# CTRL_MODULE_CORE_PAD register map
Vendor: Texas Instruments
Registers are 32-bit, access per field, reset 0x10F010F unless marked. A register's access mark holds for its fields unless they carry their own. Offsets are as the file gives them; [hi:lo] are bit positions; {n}, {i} and the like mark numbered series; 'fields as' and 'values as' point back to an identical list.

## CTRL_MODULE_CORE_PAD (part 6 of 7)
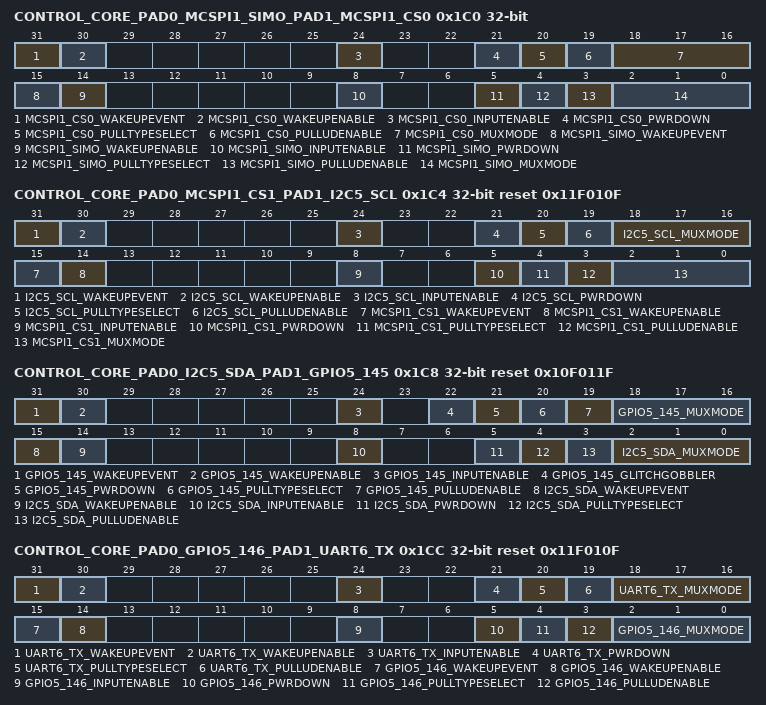
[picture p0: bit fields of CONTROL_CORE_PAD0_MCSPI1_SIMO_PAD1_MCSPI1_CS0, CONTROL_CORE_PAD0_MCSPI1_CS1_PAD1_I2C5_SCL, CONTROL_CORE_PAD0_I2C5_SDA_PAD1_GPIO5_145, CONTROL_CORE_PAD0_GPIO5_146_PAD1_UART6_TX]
0x1C0 CONTROL_CORE_PAD0_MCSPI1_SIMO_PAD1_MCSPI1_CS0 — Register control for Pads mcspi1_simo and mcspi1_cs0 Access conditions. Read: unrestricted, Write: unrestricted
  [31] MCSPI1_CS0_WAKEUPEVENT ro — Pad_x wake-up event status latched in the IO
    1=WakeUp (A wake-up event occurred); 0=No wake-up event occurred
  [30] MCSPI1_CS0_WAKEUPENABLE rw — Input pad wake-up enable
    0=DetectLow (wake-up detection is disabled); 1=DetectLowHigh (wake-up detection is enabled)
  [24] MCSPI1_CS0_INPUTENABLE rw — Input enable value for pad mcspi1_cs0
    0=InputBufferDisabled (Input buffer of IO cell is disabled); 1=InputBufferEnabled (Input buffer of IO cell is enabled)
  [21] MCSPI1_CS0_PWRDOWN rw — Power Down setting for pad mcspi1_cs0
    0=PwrDownDisabled (IO cell power is ON); 1=PwrDownEnabled (IO cell power is OFF)
  [20] MCSPI1_CS0_PULLTYPESELECT rw — Pull-Up/Down selection for pad mcspi1_cs0
    0=Pull-Down selected; 1=Pull-Up selected
  [19] MCSPI1_CS0_PULLUDENABLE rw — Pull-Up/Down enable for pad mcspi1_cs0
    0=PullDisabled (Pull-Up/Down disabled); 1=PullEnabled (Pull-Up/Down enabled)
  [18:16] MCSPI1_CS0_MUXMODE rw — Functional multiplexing selection for pad mcspi1_cs0
    0=SEL_MCSPI1_CS0 (Select mcspi1_cs0); 6=SEL_GPIO5_143 (Select gpio5_143); 7=SEL_SAFE_MODE_CORE173 (Select safe_mode_core173); 5=SEL_USBD0_ULPIPHY_DATA0 (Select usbd0_ulpiphy_data0)
  [15] MCSPI1_SIMO_WAKEUPEVENT ro — Pad_x wake-up event status latched in the IO
    values as MCSPI1_CS0_WAKEUPEVENT
  [14] MCSPI1_SIMO_WAKEUPENABLE rw — Input pad wake-up enable
    values as MCSPI1_CS0_WAKEUPENABLE
  [8] MCSPI1_SIMO_INPUTENABLE rw — Input enable value for pad mcspi1_simo
    values as MCSPI1_CS0_INPUTENABLE
  [5] MCSPI1_SIMO_PWRDOWN rw — Power Down setting for pad mcspi1_simo
    values as MCSPI1_CS0_PWRDOWN
  [4] MCSPI1_SIMO_PULLTYPESELECT rw — Pull-Up/Down selection for pad mcspi1_simo
    0=Pull-Down selected; 1=Pull-Up selected
  [3] MCSPI1_SIMO_PULLUDENABLE rw — Pull-Up/Down enable for pad mcspi1_simo
    values as MCSPI1_CS0_PULLUDENABLE
  [2:0] MCSPI1_SIMO_MUXMODE rw — Functional multiplexing selection for pad mcspi1_simo
    0=SEL_MCSPI1_SIMO (Select mcspi1_simo); 6=SEL_GPIO5_142 (Select gpio5_142); 7=SEL_SAFE_MODE_CORE172 (Select safe_mode_core172); 5=SEL_USBD0_ULPIPHY_DIR (Select usbd0_ulpiphy_dir)
0x1C4 CONTROL_CORE_PAD0_MCSPI1_CS1_PAD1_I2C5_SCL reset 0x11F010F — Register control for Pads mcspi1_cs1 and i2c5_scl Access conditions. Read: unrestricted, Write: unrestricted
  [31] I2C5_SCL_WAKEUPEVENT ro — Pad_x wake-up event status latched in the IO
    values as CONTROL_CORE_PAD0_MCSPI1_SIMO_PAD1_MCSPI1_CS0.MCSPI1_CS0_WAKEUPEVENT
  [30] I2C5_SCL_WAKEUPENABLE rw — Input pad wake-up enable
    values as CONTROL_CORE_PAD0_MCSPI1_SIMO_PAD1_MCSPI1_CS0.MCSPI1_CS0_WAKEUPENABLE
  [24] I2C5_SCL_INPUTENABLE rw — Input enable value for pad i2c5_scl
    values as CONTROL_CORE_PAD0_MCSPI1_SIMO_PAD1_MCSPI1_CS0.MCSPI1_CS0_INPUTENABLE
  [21] I2C5_SCL_PWRDOWN rw — Power Down setting for pad i2c5_scl
    values as CONTROL_CORE_PAD0_MCSPI1_SIMO_PAD1_MCSPI1_CS0.MCSPI1_CS0_PWRDOWN
  [20] I2C5_SCL_PULLTYPESELECT rw — Pull-Up/Down selection for pad i2c5_scl
    0=Pull-Down selected; 1=Pull-Up selected
  [19] I2C5_SCL_PULLUDENABLE rw — Pull-Up/Down enable for pad i2c5_scl
    values as CONTROL_CORE_PAD0_MCSPI1_SIMO_PAD1_MCSPI1_CS0.MCSPI1_CS0_PULLUDENABLE
  [18:16] I2C5_SCL_MUXMODE rw — Functional multiplexing selection for pad i2c5_scl
    0=SEL_I2C5_SCL (Select i2c5_scl); 6=SEL_GPIO5_147 (Select gpio5_147); 7=SEL_SAFE_MODE_CORE175 (Select safe_mode_core175); 2=SEL_UART4_RX (Select uart4_rx)
  [15] MCSPI1_CS1_WAKEUPEVENT ro — Pad_x wake-up event status latched in the IO
    values as CONTROL_CORE_PAD0_MCSPI1_SIMO_PAD1_MCSPI1_CS0.MCSPI1_CS0_WAKEUPEVENT
  [14] MCSPI1_CS1_WAKEUPENABLE rw — Input pad wake-up enable
    values as CONTROL_CORE_PAD0_MCSPI1_SIMO_PAD1_MCSPI1_CS0.MCSPI1_CS0_WAKEUPENABLE
  [8] MCSPI1_CS1_INPUTENABLE rw — Input enable value for pad mcspi1_cs1
    values as CONTROL_CORE_PAD0_MCSPI1_SIMO_PAD1_MCSPI1_CS0.MCSPI1_CS0_INPUTENABLE
  [5] MCSPI1_CS1_PWRDOWN rw — Power Down setting for pad mcspi1_cs1
    values as CONTROL_CORE_PAD0_MCSPI1_SIMO_PAD1_MCSPI1_CS0.MCSPI1_CS0_PWRDOWN
  [4] MCSPI1_CS1_PULLTYPESELECT rw — Pull-Up/Down selection for pad mcspi1_cs1
    0=Pull-Down selected; 1=Pull-Up selected
  [3] MCSPI1_CS1_PULLUDENABLE rw — Pull-Up/Down enable for pad mcspi1_cs1
    values as CONTROL_CORE_PAD0_MCSPI1_SIMO_PAD1_MCSPI1_CS0.MCSPI1_CS0_PULLUDENABLE
  [2:0] MCSPI1_CS1_MUXMODE rw — Functional multiplexing selection for pad mcspi1_cs1
    0=SEL_MCSPI1_CS1 (Select mcspi1_cs1); 6=SEL_GPIO5_144 (Select gpio5_144); 7=SEL_SAFE_MODE_CORE174 (Select safe_mode_core174); 5=SEL_USBD0_ULPIPHY_DATA1 (Select usbd0_ulpiphy_data1)
0x1C8 CONTROL_CORE_PAD0_I2C5_SDA_PAD1_GPIO5_145 reset 0x10F011F — Register control for Pads i2c5_sda and gpio5_145 Access conditions. Read: unrestricted, Write: unrestricted
  [31] GPIO5_145_WAKEUPEVENT ro — Pad_x wake-up event status latched in the IO
    values as CONTROL_CORE_PAD0_MCSPI1_SIMO_PAD1_MCSPI1_CS0.MCSPI1_CS0_WAKEUPEVENT
  [30] GPIO5_145_WAKEUPENABLE rw — Input pad wake-up enable
    values as CONTROL_CORE_PAD0_MCSPI1_SIMO_PAD1_MCSPI1_CS0.MCSPI1_CS0_WAKEUPENABLE
  [24] GPIO5_145_INPUTENABLE rw — Input enable value for pad gpio5_145
    values as CONTROL_CORE_PAD0_MCSPI1_SIMO_PAD1_MCSPI1_CS0.MCSPI1_CS0_INPUTENABLE
  [22] GPIO5_145_GLITCHGOBBLER rw — Glitch Gobbler setting for pad gpio5_145
    0=GlitchGobblerDisabled (IO do not Filter glitch from outside); 1=GlitchGobblerEnabled (IO Filter glitch from outside)
  [21] GPIO5_145_PWRDOWN rw — Power Down setting for pad gpio5_145
    values as CONTROL_CORE_PAD0_MCSPI1_SIMO_PAD1_MCSPI1_CS0.MCSPI1_CS0_PWRDOWN
  [20] GPIO5_145_PULLTYPESELECT rw — Pull-Up/Down selection for pad gpio5_145
    0=Pull-Down selected; 1=Pull-Up selected
  [19] GPIO5_145_PULLUDENABLE rw — Pull-Up/Down enable for pad gpio5_145
    values as CONTROL_CORE_PAD0_MCSPI1_SIMO_PAD1_MCSPI1_CS0.MCSPI1_CS0_PULLUDENABLE
  [18:16] GPIO5_145_MUXMODE rw — Functional multiplexing selection for pad gpio5_145
    6=SEL_GPIO5_145_1 (Select gpio5_145); 1=SEL_MCSPI1_CS2 (Select mcspi1_cs2); 7=SEL_SAFE_MODE_CORE177 (Select safe_mode_core177); 0=SEL_GPIO5_145 (Select gpio5_145); 2=SEL_UART4_CTS (Select uart4_cts); 5=SEL_USBD0_ULPIPHY_DATA2 (Select usbd0_ulpiphy_data2); 3=SEL_SDIO5_CLK (Select sdio5_clk)
  [15] I2C5_SDA_WAKEUPEVENT ro — Pad_x wake-up event status latched in the IO
    values as CONTROL_CORE_PAD0_MCSPI1_SIMO_PAD1_MCSPI1_CS0.MCSPI1_CS0_WAKEUPEVENT
  [14] I2C5_SDA_WAKEUPENABLE rw — Input pad wake-up enable
    values as CONTROL_CORE_PAD0_MCSPI1_SIMO_PAD1_MCSPI1_CS0.MCSPI1_CS0_WAKEUPENABLE
  [8] I2C5_SDA_INPUTENABLE rw — Input enable value for pad i2c5_sda
    values as CONTROL_CORE_PAD0_MCSPI1_SIMO_PAD1_MCSPI1_CS0.MCSPI1_CS0_INPUTENABLE
  [5] I2C5_SDA_PWRDOWN rw — Power Down setting for pad i2c5_sda
    values as CONTROL_CORE_PAD0_MCSPI1_SIMO_PAD1_MCSPI1_CS0.MCSPI1_CS0_PWRDOWN
  [4] I2C5_SDA_PULLTYPESELECT rw — Pull-Up/Down selection for pad i2c5_sda
    0=Pull-Down selected; 1=Pull-Up selected
  [3] I2C5_SDA_PULLUDENABLE rw — Pull-Up/Down enable for pad i2c5_sda
    values as CONTROL_CORE_PAD0_MCSPI1_SIMO_PAD1_MCSPI1_CS0.MCSPI1_CS0_PULLUDENABLE
  [2:0] I2C5_SDA_MUXMODE rw — Functional multiplexing selection for pad i2c5_sda
    0=SEL_I2C5_SDA (Select i2c5_sda); 6=SEL_GPIO5_148 (Select gpio5_148); 7=SEL_SAFE_MODE_CORE176 (Select safe_mode_core176); 2=SEL_UART4_TX (Select uart4_tx)
0x1CC CONTROL_CORE_PAD0_GPIO5_146_PAD1_UART6_TX reset 0x11F010F — Register control for Pads gpio5_146 and uart6_tx Access conditions. Read: unrestricted, Write: unrestricted
  [31] UART6_TX_WAKEUPEVENT ro — Pad_x wake-up event status latched in the IO
    values as CONTROL_CORE_PAD0_MCSPI1_SIMO_PAD1_MCSPI1_CS0.MCSPI1_CS0_WAKEUPEVENT
  [30] UART6_TX_WAKEUPENABLE rw — Input pad wake-up enable
    values as CONTROL_CORE_PAD0_MCSPI1_SIMO_PAD1_MCSPI1_CS0.MCSPI1_CS0_WAKEUPENABLE
  [24] UART6_TX_INPUTENABLE rw — Input enable value for pad uart6_tx
    values as CONTROL_CORE_PAD0_MCSPI1_SIMO_PAD1_MCSPI1_CS0.MCSPI1_CS0_INPUTENABLE
  [21] UART6_TX_PWRDOWN rw — Power Down setting for pad uart6_tx
    values as CONTROL_CORE_PAD0_MCSPI1_SIMO_PAD1_MCSPI1_CS0.MCSPI1_CS0_PWRDOWN
  [20] UART6_TX_PULLTYPESELECT rw — Pull-Up/Down selection for pad uart6_tx
    0=Pull-Down selected; 1=Pull-Up selected
  [19] UART6_TX_PULLUDENABLE rw — Pull-Up/Down enable for pad uart6_tx
    values as CONTROL_CORE_PAD0_MCSPI1_SIMO_PAD1_MCSPI1_CS0.MCSPI1_CS0_PULLUDENABLE
  [18:16] UART6_TX_MUXMODE rw — Functional multiplexing selection for pad uart6_tx
    0=SEL_UART6_TX (Select uart6_tx); 3=SEL_SDIO5_DATA3 (Select sdio5_data3); 7=SEL_SAFE_MODE_CORE179 (Select safe_mode_core179); 4=SEL_USBB2_MM_RXDP (Select usbb2_mm_rxdp); 6=SEL_GPIO5_149 (Select gpio5_149)
  [15] GPIO5_146_WAKEUPEVENT ro — Pad_x wake-up event status latched in the IO
    values as CONTROL_CORE_PAD0_MCSPI1_SIMO_PAD1_MCSPI1_CS0.MCSPI1_CS0_WAKEUPEVENT
  [14] GPIO5_146_WAKEUPENABLE rw — Input pad wake-up enable
    values as CONTROL_CORE_PAD0_MCSPI1_SIMO_PAD1_MCSPI1_CS0.MCSPI1_CS0_WAKEUPENABLE
  [8] GPIO5_146_INPUTENABLE rw — Input enable value for pad gpio5_146
    values as CONTROL_CORE_PAD0_MCSPI1_SIMO_PAD1_MCSPI1_CS0.MCSPI1_CS0_INPUTENABLE
  [5] GPIO5_146_PWRDOWN rw — Power Down setting for pad gpio5_146
    values as CONTROL_CORE_PAD0_MCSPI1_SIMO_PAD1_MCSPI1_CS0.MCSPI1_CS0_PWRDOWN
  [4] GPIO5_146_PULLTYPESELECT rw — Pull-Up/Down selection for pad gpio5_146
    0=Pull-Down selected; 1=Pull-Up selected
  [3] GPIO5_146_PULLUDENABLE rw — Pull-Up/Down enable for pad gpio5_146
    values as CONTROL_CORE_PAD0_MCSPI1_SIMO_PAD1_MCSPI1_CS0.MCSPI1_CS0_PULLUDENABLE
  [2:0] GPIO5_146_MUXMODE rw — Functional multiplexing selection for pad gpio5_146
    6=SEL_GPIO5_146_1 (Select gpio5_146); 1=SEL_MCSPI1_CS3 (Select mcspi1_cs3); 7=SEL_SAFE_MODE_CORE178 (Select safe_mode_core178); 0=SEL_GPIO5_146 (Select gpio5_146); 2=SEL_UART4_RTS (Select uart4_rts); 5=SEL_USBD0_ULPIPHY_DATA3 (Select usbd0_ulpiphy_data3); 3=SEL_SDIO5_CMD (Select sdio5_cmd)
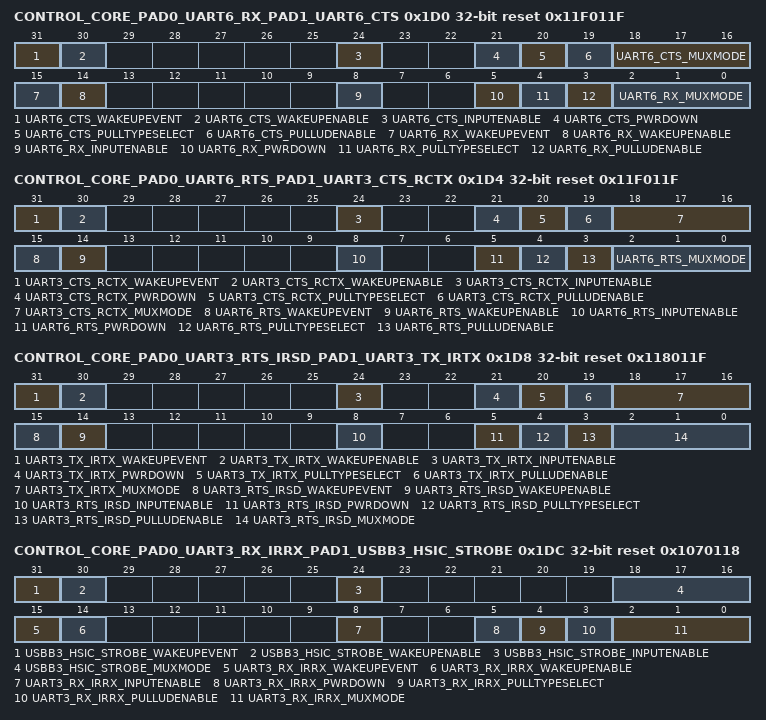
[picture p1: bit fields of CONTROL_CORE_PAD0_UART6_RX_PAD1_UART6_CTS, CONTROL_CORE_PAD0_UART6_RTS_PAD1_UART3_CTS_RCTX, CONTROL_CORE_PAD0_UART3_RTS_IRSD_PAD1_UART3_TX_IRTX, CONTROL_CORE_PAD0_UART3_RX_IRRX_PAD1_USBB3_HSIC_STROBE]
0x1D0 CONTROL_CORE_PAD0_UART6_RX_PAD1_UART6_CTS reset 0x11F011F — Register control for Pads uart6_rx and uart6_cts Access conditions. Read: unrestricted, Write: unrestricted
  [31] UART6_CTS_WAKEUPEVENT ro — Pad_x wake-up event status latched in the IO
    values as CONTROL_CORE_PAD0_MCSPI1_SIMO_PAD1_MCSPI1_CS0.MCSPI1_CS0_WAKEUPEVENT
  [30] UART6_CTS_WAKEUPENABLE rw — Input pad wake-up enable
    values as CONTROL_CORE_PAD0_MCSPI1_SIMO_PAD1_MCSPI1_CS0.MCSPI1_CS0_WAKEUPENABLE
  [24] UART6_CTS_INPUTENABLE rw — Input enable value for pad uart6_cts
    values as CONTROL_CORE_PAD0_MCSPI1_SIMO_PAD1_MCSPI1_CS0.MCSPI1_CS0_INPUTENABLE
  [21] UART6_CTS_PWRDOWN rw — Power Down setting for pad uart6_cts
    values as CONTROL_CORE_PAD0_MCSPI1_SIMO_PAD1_MCSPI1_CS0.MCSPI1_CS0_PWRDOWN
  [20] UART6_CTS_PULLTYPESELECT rw — Pull-Up/Down selection for pad uart6_cts
    0=Pull-Down selected; 1=Pull-Up selected
  [19] UART6_CTS_PULLUDENABLE rw — Pull-Up/Down enable for pad uart6_cts
    values as CONTROL_CORE_PAD0_MCSPI1_SIMO_PAD1_MCSPI1_CS0.MCSPI1_CS0_PULLUDENABLE
  [18:16] UART6_CTS_MUXMODE rw — Functional multiplexing selection for pad uart6_cts
    0=SEL_UART6_CTS (Select uart6_cts); 1=SEL_SYS_NDMAREQ1 (Select sys_ndmareq1); 3=SEL_SDIO5_DATA1 (Select sdio5_data1); 7=SEL_SAFE_MODE_CORE181 (Select safe_mode_core181); 4=SEL_USBB2_MM_RXRCV (Select usbb2_mm_rxrcv); 6=SEL_GPIO5_151 (Select gpio5_151)
  [15] UART6_RX_WAKEUPEVENT ro — Pad_x wake-up event status latched in the IO
    values as CONTROL_CORE_PAD0_MCSPI1_SIMO_PAD1_MCSPI1_CS0.MCSPI1_CS0_WAKEUPEVENT
  [14] UART6_RX_WAKEUPENABLE rw — Input pad wake-up enable
    values as CONTROL_CORE_PAD0_MCSPI1_SIMO_PAD1_MCSPI1_CS0.MCSPI1_CS0_WAKEUPENABLE
  [8] UART6_RX_INPUTENABLE rw — Input enable value for pad uart6_rx
    values as CONTROL_CORE_PAD0_MCSPI1_SIMO_PAD1_MCSPI1_CS0.MCSPI1_CS0_INPUTENABLE
  [5] UART6_RX_PWRDOWN rw — Power Down setting for pad uart6_rx
    values as CONTROL_CORE_PAD0_MCSPI1_SIMO_PAD1_MCSPI1_CS0.MCSPI1_CS0_PWRDOWN
  [4] UART6_RX_PULLTYPESELECT rw — Pull-Up/Down selection for pad uart6_rx
    0=Pull-Down selected; 1=Pull-Up selected
  [3] UART6_RX_PULLUDENABLE rw — Pull-Up/Down enable for pad uart6_rx
    values as CONTROL_CORE_PAD0_MCSPI1_SIMO_PAD1_MCSPI1_CS0.MCSPI1_CS0_PULLUDENABLE
  [2:0] UART6_RX_MUXMODE rw — Functional multiplexing selection for pad uart6_rx
    0=SEL_UART6_RX (Select uart6_rx); 3=SEL_SDIO5_DATA2 (Select sdio5_data2); 7=SEL_SAFE_MODE_CORE180 (Select safe_mode_core180); 4=SEL_USBB2_MM_RXDM (Select usbb2_mm_rxdm); 6=SEL_GPIO5_150 (Select gpio5_150)
0x1D4 CONTROL_CORE_PAD0_UART6_RTS_PAD1_UART3_CTS_RCTX reset 0x11F011F — Register control for Pads uart6_rts and uart3_cts_rctx Access conditions. Read: unrestricted, Write: unrestricted
  [31] UART3_CTS_RCTX_WAKEUPEVENT ro — Pad_x wake-up event status latched in the IO
    values as CONTROL_CORE_PAD0_MCSPI1_SIMO_PAD1_MCSPI1_CS0.MCSPI1_CS0_WAKEUPEVENT
  [30] UART3_CTS_RCTX_WAKEUPENABLE rw — Input pad wake-up enable
    values as CONTROL_CORE_PAD0_MCSPI1_SIMO_PAD1_MCSPI1_CS0.MCSPI1_CS0_WAKEUPENABLE
  [24] UART3_CTS_RCTX_INPUTENABLE rw — Input enable value for pad uart3_cts_rctx
    values as CONTROL_CORE_PAD0_MCSPI1_SIMO_PAD1_MCSPI1_CS0.MCSPI1_CS0_INPUTENABLE
  [21] UART3_CTS_RCTX_PWRDOWN rw — Power Down setting for pad uart3_cts_rctx
    values as CONTROL_CORE_PAD0_MCSPI1_SIMO_PAD1_MCSPI1_CS0.MCSPI1_CS0_PWRDOWN
  [20] UART3_CTS_RCTX_PULLTYPESELECT rw — Pull-Up/Down selection for pad uart3_cts_rctx
    0=Pull-Down selected; 1=Pull-Up selected
  [19] UART3_CTS_RCTX_PULLUDENABLE rw — Pull-Up/Down enable for pad uart3_cts_rctx
    values as CONTROL_CORE_PAD0_MCSPI1_SIMO_PAD1_MCSPI1_CS0.MCSPI1_CS0_PULLUDENABLE
  [18:16] UART3_CTS_RCTX_MUXMODE rw — Functional multiplexing selection for pad uart3_cts_rctx
    6=SEL_GPIO5_153 (Select gpio5_153); 1=SEL_SATA_ACTLED (Select sata_actled); 7=SEL_SAFE_MODE_CORE183 (Select safe_mode_core183); 0=SEL_UART3_CTS_RCTX (Select uart3_cts_rctx); 4=SEL_USBB2_MM_TXEN (Select usbb2_mm_txen); 5=SEL_USBD0_ULPIPHY_DATA4 (Select usbd0_ulpiphy_data4); 3=SEL_SDIO5_DATA7 (Select sdio5_data7)
  [15] UART6_RTS_WAKEUPEVENT ro — Pad_x wake-up event status latched in the IO
    values as CONTROL_CORE_PAD0_MCSPI1_SIMO_PAD1_MCSPI1_CS0.MCSPI1_CS0_WAKEUPEVENT
  [14] UART6_RTS_WAKEUPENABLE rw — Input pad wake-up enable
    values as CONTROL_CORE_PAD0_MCSPI1_SIMO_PAD1_MCSPI1_CS0.MCSPI1_CS0_WAKEUPENABLE
  [8] UART6_RTS_INPUTENABLE rw — Input enable value for pad uart6_rts
    values as CONTROL_CORE_PAD0_MCSPI1_SIMO_PAD1_MCSPI1_CS0.MCSPI1_CS0_INPUTENABLE
  [5] UART6_RTS_PWRDOWN rw — Power Down setting for pad uart6_rts
    values as CONTROL_CORE_PAD0_MCSPI1_SIMO_PAD1_MCSPI1_CS0.MCSPI1_CS0_PWRDOWN
  [4] UART6_RTS_PULLTYPESELECT rw — Pull-Up/Down selection for pad uart6_rts
    0=Pull-Down selected; 1=Pull-Up selected
  [3] UART6_RTS_PULLUDENABLE rw — Pull-Up/Down enable for pad uart6_rts
    values as CONTROL_CORE_PAD0_MCSPI1_SIMO_PAD1_MCSPI1_CS0.MCSPI1_CS0_PULLUDENABLE
  [2:0] UART6_RTS_MUXMODE rw — Functional multiplexing selection for pad uart6_rts
    6=SEL_GPIO5_152 (Select gpio5_152); 1=SEL_SYS_NDMAREQ0 (Select sys_ndmareq0); 7=SEL_SAFE_MODE_CORE182 (Select safe_mode_core182); 0=SEL_UART6_RTS (Select uart6_rts); 4=SEL_USBB2_MM_TXSE0 (Select usbb2_mm_txse0); 5=SEL_USBD0_ULPIPHY_STP (Select usbd0_ulpiphy_stp); 3=SEL_SDIO5_DATA0 (Select sdio5_data0)
0x1D8 CONTROL_CORE_PAD0_UART3_RTS_IRSD_PAD1_UART3_TX_IRTX reset 0x118011F — Register control for Pads uart3_rts_irsd and uart3_tx_irtx Access conditions. Read: unrestricted, Write: unrestricted
  [31] UART3_TX_IRTX_WAKEUPEVENT ro — Pad_x wake-up event status latched in the IO
    values as CONTROL_CORE_PAD0_MCSPI1_SIMO_PAD1_MCSPI1_CS0.MCSPI1_CS0_WAKEUPEVENT
  [30] UART3_TX_IRTX_WAKEUPENABLE rw — Input pad wake-up enable
    values as CONTROL_CORE_PAD0_MCSPI1_SIMO_PAD1_MCSPI1_CS0.MCSPI1_CS0_WAKEUPENABLE
  [24] UART3_TX_IRTX_INPUTENABLE rw — Input enable value for pad uart3_tx_irtx
    values as CONTROL_CORE_PAD0_MCSPI1_SIMO_PAD1_MCSPI1_CS0.MCSPI1_CS0_INPUTENABLE
  [21] UART3_TX_IRTX_PWRDOWN rw — Power Down setting for pad uart3_tx_irtx
    values as CONTROL_CORE_PAD0_MCSPI1_SIMO_PAD1_MCSPI1_CS0.MCSPI1_CS0_PWRDOWN
  [20] UART3_TX_IRTX_PULLTYPESELECT rw — Pull-Up/Down selection for pad uart3_tx_irtx
    0=Pull-Down selected; 1=Pull-Up selected
  [19] UART3_TX_IRTX_PULLUDENABLE rw — Pull-Up/Down enable for pad uart3_tx_irtx
    values as CONTROL_CORE_PAD0_MCSPI1_SIMO_PAD1_MCSPI1_CS0.MCSPI1_CS0_PULLUDENABLE
  [18:16] UART3_TX_IRTX_MUXMODE rw — Functional multiplexing selection for pad uart3_tx_irtx
    6=SEL_GPIO5_155 (Select gpio5_155); 7=SEL_SAFE_MODE_CORE185 (Select safe_mode_core185); 0=SEL_UART3_TX_IRTX (Select uart3_tx_irtx); 4=SEL_SDIO4_CLK (Select sdio4_clk); 5=SEL_USBD0_ULPIPHY_DATA6 (Select usbd0_ulpiphy_data6); 3=SEL_SDIO5_DATA5 (Select sdio5_data5)
  [15] UART3_RTS_IRSD_WAKEUPEVENT ro — Pad_x wake-up event status latched in the IO
    values as CONTROL_CORE_PAD0_MCSPI1_SIMO_PAD1_MCSPI1_CS0.MCSPI1_CS0_WAKEUPEVENT
  [14] UART3_RTS_IRSD_WAKEUPENABLE rw — Input pad wake-up enable
    values as CONTROL_CORE_PAD0_MCSPI1_SIMO_PAD1_MCSPI1_CS0.MCSPI1_CS0_WAKEUPENABLE
  [8] UART3_RTS_IRSD_INPUTENABLE rw — Input enable value for pad uart3_rts_irsd
    values as CONTROL_CORE_PAD0_MCSPI1_SIMO_PAD1_MCSPI1_CS0.MCSPI1_CS0_INPUTENABLE
  [5] UART3_RTS_IRSD_PWRDOWN rw — Power Down setting for pad uart3_rts_irsd
    values as CONTROL_CORE_PAD0_MCSPI1_SIMO_PAD1_MCSPI1_CS0.MCSPI1_CS0_PWRDOWN
  [4] UART3_RTS_IRSD_PULLTYPESELECT rw — Pull-Up/Down selection for pad uart3_rts_irsd
    0=Pull-Down selected; 1=Pull-Up selected
  [3] UART3_RTS_IRSD_PULLUDENABLE rw — Pull-Up/Down enable for pad uart3_rts_irsd
    values as CONTROL_CORE_PAD0_MCSPI1_SIMO_PAD1_MCSPI1_CS0.MCSPI1_CS0_PULLUDENABLE
  [2:0] UART3_RTS_IRSD_MUXMODE rw — Functional multiplexing selection for pad uart3_rts_irsd
    6=SEL_GPIO5_154 (Select gpio5_154); 1=SEL_HDQ_SIO (Select hdq_sio); 7=SEL_SAFE_MODE_CORE184 (Select safe_mode_core184); 0=SEL_UART3_RTS_IRSD (Select uart3_rts_irsd); 4=SEL_USBB2_MM_TXDAT (Select usbb2_mm_txdat); 5=SEL_USBD0_ULPIPHY_DATA5 (Select usbd0_ulpiphy_data5); 3=SEL_SDIO5_DATA6 (Select sdio5_data6)
0x1DC CONTROL_CORE_PAD0_UART3_RX_IRRX_PAD1_USBB3_HSIC_STROBE reset 0x1070118 — Register control for Pads uart3_rx_irrx and usbb3_hsic_strobe Access conditions. Read: unrestricted, Write: unrestricted
  [31] USBB3_HSIC_STROBE_WAKEUPEVENT ro — Pad_x wake-up event status latched in the IO
    values as CONTROL_CORE_PAD0_MCSPI1_SIMO_PAD1_MCSPI1_CS0.MCSPI1_CS0_WAKEUPEVENT
  [30] USBB3_HSIC_STROBE_WAKEUPENABLE rw — Input pad wake-up enable
    values as CONTROL_CORE_PAD0_MCSPI1_SIMO_PAD1_MCSPI1_CS0.MCSPI1_CS0_WAKEUPENABLE
  [24] USBB3_HSIC_STROBE_INPUTENABLE rw — Input enable value for pad usbb3_hsic_strobe
    values as CONTROL_CORE_PAD0_MCSPI1_SIMO_PAD1_MCSPI1_CS0.MCSPI1_CS0_INPUTENABLE
  [18:16] USBB3_HSIC_STROBE_MUXMODE rw — Functional multiplexing selection for pad usbb3_hsic_strobe
    0=SEL_USBB3_HSIC_STROBE (Select usbb3_hsic_strobe); 7=SEL_SAFE_MODE_CORE187 (Select safe_mode_core187); 6=SEL_GPIO5_158 (Select gpio5_158)
  [15] UART3_RX_IRRX_WAKEUPEVENT ro — Pad_x wake-up event status latched in the IO
    values as CONTROL_CORE_PAD0_MCSPI1_SIMO_PAD1_MCSPI1_CS0.MCSPI1_CS0_WAKEUPEVENT
  [14] UART3_RX_IRRX_WAKEUPENABLE rw — Input pad wake-up enable
    values as CONTROL_CORE_PAD0_MCSPI1_SIMO_PAD1_MCSPI1_CS0.MCSPI1_CS0_WAKEUPENABLE
  [8] UART3_RX_IRRX_INPUTENABLE rw — Input enable value for pad uart3_rx_irrx
    values as CONTROL_CORE_PAD0_MCSPI1_SIMO_PAD1_MCSPI1_CS0.MCSPI1_CS0_INPUTENABLE
  [5] UART3_RX_IRRX_PWRDOWN rw — Power Down setting for pad uart3_rx_irrx
    values as CONTROL_CORE_PAD0_MCSPI1_SIMO_PAD1_MCSPI1_CS0.MCSPI1_CS0_PWRDOWN
  [4] UART3_RX_IRRX_PULLTYPESELECT rw — Pull-Up/Down selection for pad uart3_rx_irrx
    0=Pull-Down selected; 1=Pull-Up selected
  [3] UART3_RX_IRRX_PULLUDENABLE rw — Pull-Up/Down enable for pad uart3_rx_irrx
    values as CONTROL_CORE_PAD0_MCSPI1_SIMO_PAD1_MCSPI1_CS0.MCSPI1_CS0_PULLUDENABLE
  [2:0] UART3_RX_IRRX_MUXMODE rw — Functional multiplexing selection for pad uart3_rx_irrx
    6=SEL_GPIO5_156 (Select gpio5_156); 7=SEL_SAFE_MODE_CORE186 (Select safe_mode_core186); 0=SEL_UART3_RX_IRRX (Select uart3_rx_irrx); 4=SEL_SDIO4_CMD (Select sdio4_cmd); 5=SEL_USBD0_ULPIPHY_DATA7 (Select usbd0_ulpiphy_data7); 3=SEL_SDIO5_DATA4 (Select sdio5_data4)
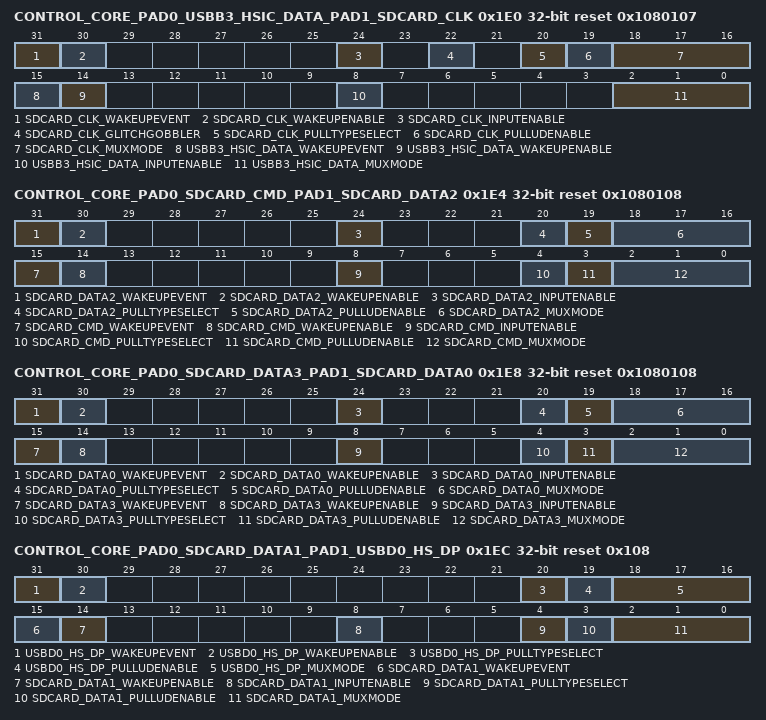
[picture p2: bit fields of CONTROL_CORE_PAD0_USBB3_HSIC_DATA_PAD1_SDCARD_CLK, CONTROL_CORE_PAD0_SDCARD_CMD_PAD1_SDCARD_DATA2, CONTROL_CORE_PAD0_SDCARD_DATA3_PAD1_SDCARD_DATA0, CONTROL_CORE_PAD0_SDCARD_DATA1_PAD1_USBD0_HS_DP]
0x1E0 CONTROL_CORE_PAD0_USBB3_HSIC_DATA_PAD1_SDCARD_CLK reset 0x1080107 — Register control for Pads usbb3_hsic_data and sdcard_clk Access conditions. Read: unrestricted, Write: unrestricted
  [31] SDCARD_CLK_WAKEUPEVENT ro — Pad_x wake-up event status latched in the IO
    values as CONTROL_CORE_PAD0_MCSPI1_SIMO_PAD1_MCSPI1_CS0.MCSPI1_CS0_WAKEUPEVENT
  [30] SDCARD_CLK_WAKEUPENABLE rw — Input pad wake-up enable
    values as CONTROL_CORE_PAD0_MCSPI1_SIMO_PAD1_MCSPI1_CS0.MCSPI1_CS0_WAKEUPENABLE
  [24] SDCARD_CLK_INPUTENABLE rw — Input enable value for pad sdcard_clk
    values as CONTROL_CORE_PAD0_MCSPI1_SIMO_PAD1_MCSPI1_CS0.MCSPI1_CS0_INPUTENABLE
  [22] SDCARD_CLK_GLITCHGOBBLER rw — Glitch Gobbler setting for pad sdcard_clk
    values as CONTROL_CORE_PAD0_I2C5_SDA_PAD1_GPIO5_145.GPIO5_145_GLITCHGOBBLER
  [20] SDCARD_CLK_PULLTYPESELECT rw — Pull-Up/Down selection for pad sdcard_clk
    0=Pull-Down selected; 1=Pull-Up selected
  [19] SDCARD_CLK_PULLUDENABLE rw — Pull-Up/Down enable for pad sdcard_clk
    values as CONTROL_CORE_PAD0_MCSPI1_SIMO_PAD1_MCSPI1_CS0.MCSPI1_CS0_PULLUDENABLE
  [18:16] SDCARD_CLK_MUXMODE rw — Functional multiplexing selection for pad sdcard_clk
    0=SEL_SDCARD_CLK (Select sdcard_clk); 3=SEL_JTAG_RTCK (Select jtag_rtck); 7=SEL_SAFE_MODE_CORE189 (Select safe_mode_core189); 5=SEL_N_CLK (Select n_clk)
  [15] USBB3_HSIC_DATA_WAKEUPEVENT ro — Pad_x wake-up event status latched in the IO
    values as CONTROL_CORE_PAD0_MCSPI1_SIMO_PAD1_MCSPI1_CS0.MCSPI1_CS0_WAKEUPEVENT
  [14] USBB3_HSIC_DATA_WAKEUPENABLE rw — Input pad wake-up enable
    values as CONTROL_CORE_PAD0_MCSPI1_SIMO_PAD1_MCSPI1_CS0.MCSPI1_CS0_WAKEUPENABLE
  [8] USBB3_HSIC_DATA_INPUTENABLE rw — Input enable value for pad usbb3_hsic_data
    values as CONTROL_CORE_PAD0_MCSPI1_SIMO_PAD1_MCSPI1_CS0.MCSPI1_CS0_INPUTENABLE
  [2:0] USBB3_HSIC_DATA_MUXMODE rw — Functional multiplexing selection for pad usbb3_hsic_data
    0=SEL_USBB3_HSIC_DATA (Select usbb3_hsic_data); 7=SEL_SAFE_MODE_CORE188 (Select safe_mode_core188); 6=SEL_GPIO5_159 (Select gpio5_159)
0x1E4 CONTROL_CORE_PAD0_SDCARD_CMD_PAD1_SDCARD_DATA2 reset 0x1080108 — Register control for Pads sdcard_cmd and sdcard_data2 Access conditions. Read: unrestricted, Write: unrestricted
  [31] SDCARD_DATA2_WAKEUPEVENT ro — Pad_x wake-up event status latched in the IO
    values as CONTROL_CORE_PAD0_MCSPI1_SIMO_PAD1_MCSPI1_CS0.MCSPI1_CS0_WAKEUPEVENT
  [30] SDCARD_DATA2_WAKEUPENABLE rw — Input pad wake-up enable
    values as CONTROL_CORE_PAD0_MCSPI1_SIMO_PAD1_MCSPI1_CS0.MCSPI1_CS0_WAKEUPENABLE
  [24] SDCARD_DATA2_INPUTENABLE rw — Input enable value for pad sdcard_data2
    values as CONTROL_CORE_PAD0_MCSPI1_SIMO_PAD1_MCSPI1_CS0.MCSPI1_CS0_INPUTENABLE
  [20] SDCARD_DATA2_PULLTYPESELECT rw — Pull-Up/Down selection for pad sdcard_data2
    0=Pull-Down selected; 1=Pull-Up selected
  [19] SDCARD_DATA2_PULLUDENABLE rw — Pull-Up/Down enable for pad sdcard_data2
    values as CONTROL_CORE_PAD0_MCSPI1_SIMO_PAD1_MCSPI1_CS0.MCSPI1_CS0_PULLUDENABLE
  [18:16] SDCARD_DATA2_MUXMODE rw — Functional multiplexing selection for pad sdcard_data2
    0=SEL_SDCARD_DATA2 (Select sdcard_data2); 3=SEL_JTAG_TMSC (Select jtag_tmsc); 7=SEL_SAFE_MODE_CORE193 (Select safe_mode_core193); 5=SEL_N_D2 (Select n_d2)
  [15] SDCARD_CMD_WAKEUPEVENT ro — Pad_x wake-up event status latched in the IO
    values as CONTROL_CORE_PAD0_MCSPI1_SIMO_PAD1_MCSPI1_CS0.MCSPI1_CS0_WAKEUPEVENT
  [14] SDCARD_CMD_WAKEUPENABLE rw — Input pad wake-up enable
    values as CONTROL_CORE_PAD0_MCSPI1_SIMO_PAD1_MCSPI1_CS0.MCSPI1_CS0_WAKEUPENABLE
  [8] SDCARD_CMD_INPUTENABLE rw — Input enable value for pad sdcard_cmd
    values as CONTROL_CORE_PAD0_MCSPI1_SIMO_PAD1_MCSPI1_CS0.MCSPI1_CS0_INPUTENABLE
  [4] SDCARD_CMD_PULLTYPESELECT rw — Pull-Up/Down selection for pad sdcard_cmd
    0=Pull-Down selected; 1=Pull-Up selected
  [3] SDCARD_CMD_PULLUDENABLE rw — Pull-Up/Down enable for pad sdcard_cmd
    values as CONTROL_CORE_PAD0_MCSPI1_SIMO_PAD1_MCSPI1_CS0.MCSPI1_CS0_PULLUDENABLE
  [2:0] SDCARD_CMD_MUXMODE rw — Functional multiplexing selection for pad sdcard_cmd
    0=SEL_SDCARD_CMD (Select sdcard_cmd); 3=SEL_JTAG_TDO (Select jtag_tdo); 7=SEL_SAFE_MODE_CORE190 (Select safe_mode_core190); 4=SEL_UART6_RX (Select uart6_rx); 6=SEL_N_D2 (Select n_d2)
0x1E8 CONTROL_CORE_PAD0_SDCARD_DATA3_PAD1_SDCARD_DATA0 reset 0x1080108 — Register control for Pads sdcard_data3 and sdcard_data0 Access conditions. Read: unrestricted, Write: unrestricted
  [31] SDCARD_DATA0_WAKEUPEVENT ro — Pad_x wake-up event status latched in the IO
    values as CONTROL_CORE_PAD0_MCSPI1_SIMO_PAD1_MCSPI1_CS0.MCSPI1_CS0_WAKEUPEVENT
  [30] SDCARD_DATA0_WAKEUPENABLE rw — Input pad wake-up enable
    values as CONTROL_CORE_PAD0_MCSPI1_SIMO_PAD1_MCSPI1_CS0.MCSPI1_CS0_WAKEUPENABLE
  [24] SDCARD_DATA0_INPUTENABLE rw — Input enable value for pad sdcard_data0
    values as CONTROL_CORE_PAD0_MCSPI1_SIMO_PAD1_MCSPI1_CS0.MCSPI1_CS0_INPUTENABLE
  [20] SDCARD_DATA0_PULLTYPESELECT rw — Pull-Up/Down selection for pad sdcard_data0
    0=Pull-Down selected; 1=Pull-Up selected
  [19] SDCARD_DATA0_PULLUDENABLE rw — Pull-Up/Down enable for pad sdcard_data0
    values as CONTROL_CORE_PAD0_MCSPI1_SIMO_PAD1_MCSPI1_CS0.MCSPI1_CS0_PULLUDENABLE
  [18:16] SDCARD_DATA0_MUXMODE rw — Functional multiplexing selection for pad sdcard_data0
    0=SEL_SDCARD_DATA0 (Select sdcard_data0); 3=SEL_JTAG_TDI (Select jtag_tdi); 7=SEL_SAFE_MODE_CORE191 (Select safe_mode_core191); 5=SEL_N_D0 (Select n_d0)
  [15] SDCARD_DATA3_WAKEUPEVENT ro — Pad_x wake-up event status latched in the IO
    values as CONTROL_CORE_PAD0_MCSPI1_SIMO_PAD1_MCSPI1_CS0.MCSPI1_CS0_WAKEUPEVENT
  [14] SDCARD_DATA3_WAKEUPENABLE rw — Input pad wake-up enable
    values as CONTROL_CORE_PAD0_MCSPI1_SIMO_PAD1_MCSPI1_CS0.MCSPI1_CS0_WAKEUPENABLE
  [8] SDCARD_DATA3_INPUTENABLE rw — Input enable value for pad sdcard_data3
    values as CONTROL_CORE_PAD0_MCSPI1_SIMO_PAD1_MCSPI1_CS0.MCSPI1_CS0_INPUTENABLE
  [4] SDCARD_DATA3_PULLTYPESELECT rw — Pull-Up/Down selection for pad sdcard_data3
    0=Pull-Down selected; 1=Pull-Up selected
  [3] SDCARD_DATA3_PULLUDENABLE rw — Pull-Up/Down enable for pad sdcard_data3
    values as CONTROL_CORE_PAD0_MCSPI1_SIMO_PAD1_MCSPI1_CS0.MCSPI1_CS0_PULLUDENABLE
  [2:0] SDCARD_DATA3_MUXMODE rw — Functional multiplexing selection for pad sdcard_data3
    0=SEL_SDCARD_DATA3 (Select sdcard_data3); 3=SEL_JTAG_TCK (Select jtag_tck); 7=SEL_SAFE_MODE_CORE194 (Select safe_mode_core194); 5=SEL_N_D3 (Select n_d3)
0x1EC CONTROL_CORE_PAD0_SDCARD_DATA1_PAD1_USBD0_HS_DP reset 0x108 — Register control for Pads sdcard_data1 and usbd0_hs_dp Access conditions. Read: unrestricted, Write: unrestricted
  [31] USBD0_HS_DP_WAKEUPEVENT ro — Pad_x wake-up event status latched in the IO
    values as CONTROL_CORE_PAD0_MCSPI1_SIMO_PAD1_MCSPI1_CS0.MCSPI1_CS0_WAKEUPEVENT
  [30] USBD0_HS_DP_WAKEUPENABLE rw — Input pad wake-up enable
    values as CONTROL_CORE_PAD0_MCSPI1_SIMO_PAD1_MCSPI1_CS0.MCSPI1_CS0_WAKEUPENABLE
  [20] USBD0_HS_DP_PULLTYPESELECT rw — Pull-Up/Down selection for pad usbd0_hs_dp
    0=Pull-Down selected; 1=Pull-Up selected
  [19] USBD0_HS_DP_PULLUDENABLE rw — Pull-Up/Down enable for pad usbd0_hs_dp
    values as CONTROL_CORE_PAD0_MCSPI1_SIMO_PAD1_MCSPI1_CS0.MCSPI1_CS0_PULLUDENABLE
  [18:16] USBD0_HS_DP_MUXMODE rw — Functional multiplexing selection for pad usbd0_hs_dp
    0=SEL_USBD0_HS_DP (Select usbd0_hs_dp); 4=SEL_UART3_RX_IRRX (Select uart3_rx_irrx); 7=SEL_SAFE_MODE_CORE195 (Select safe_mode_core195)
  [15] SDCARD_DATA1_WAKEUPEVENT ro — Pad_x wake-up event status latched in the IO
    values as CONTROL_CORE_PAD0_MCSPI1_SIMO_PAD1_MCSPI1_CS0.MCSPI1_CS0_WAKEUPEVENT
  [14] SDCARD_DATA1_WAKEUPENABLE rw — Input pad wake-up enable
    values as CONTROL_CORE_PAD0_MCSPI1_SIMO_PAD1_MCSPI1_CS0.MCSPI1_CS0_WAKEUPENABLE
  [8] SDCARD_DATA1_INPUTENABLE rw — Input enable value for pad sdcard_data1
    values as CONTROL_CORE_PAD0_MCSPI1_SIMO_PAD1_MCSPI1_CS0.MCSPI1_CS0_INPUTENABLE
  [4] SDCARD_DATA1_PULLTYPESELECT rw — Pull-Up/Down selection for pad sdcard_data1
    0=Pull-Down selected; 1=Pull-Up selected
  [3] SDCARD_DATA1_PULLUDENABLE rw — Pull-Up/Down enable for pad sdcard_data1
    values as CONTROL_CORE_PAD0_MCSPI1_SIMO_PAD1_MCSPI1_CS0.MCSPI1_CS0_PULLUDENABLE
  [2:0] SDCARD_DATA1_MUXMODE rw — Functional multiplexing selection for pad sdcard_data1
    0=SEL_SDCARD_DATA1 (Select sdcard_data1); 3=SEL_JTAG_NTRST (Select jtag_ntrst); 7=SEL_SAFE_MODE_CORE192 (Select safe_mode_core192); 5=SEL_N_D1 (Select n_d1)
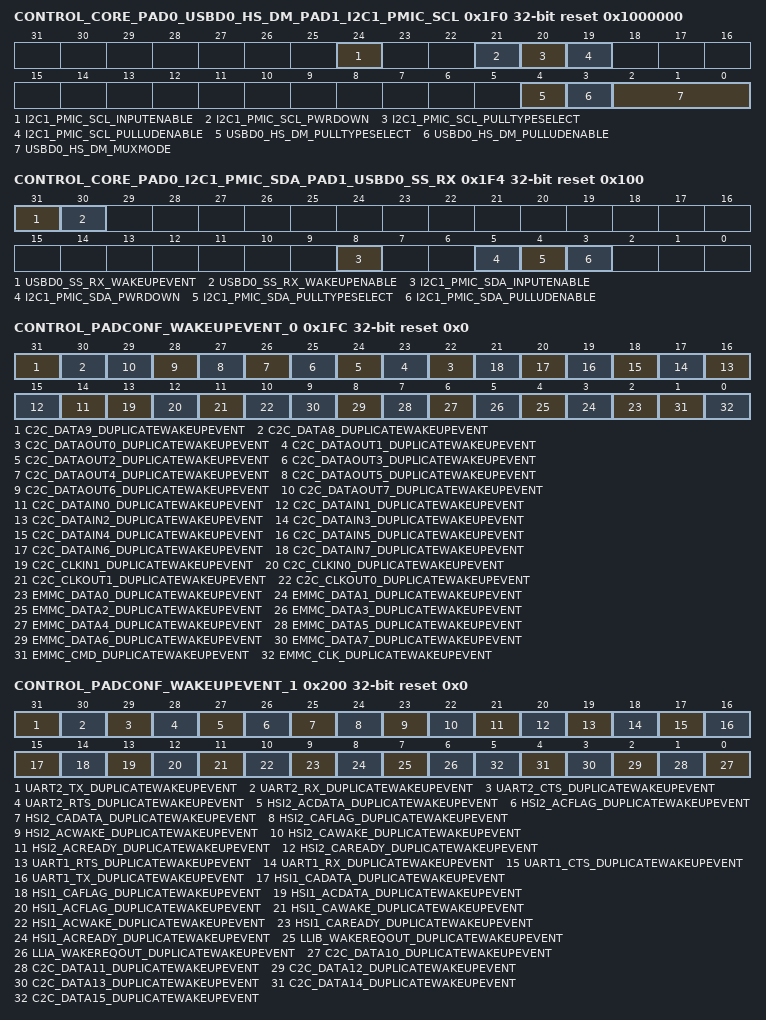
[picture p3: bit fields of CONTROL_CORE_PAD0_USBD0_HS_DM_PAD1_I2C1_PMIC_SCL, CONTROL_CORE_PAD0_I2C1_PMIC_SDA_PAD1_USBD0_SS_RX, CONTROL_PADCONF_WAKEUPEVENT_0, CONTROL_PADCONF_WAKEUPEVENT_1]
0x1F0 CONTROL_CORE_PAD0_USBD0_HS_DM_PAD1_I2C1_PMIC_SCL reset 0x1000000 — Register control for Pads usbd0_hs_dm and i2c1_pmic_scl Access conditions. Read: unrestricted, Write: unrestricted
  [24] I2C1_PMIC_SCL_INPUTENABLE rw — Input enable value for pad i2c1_pmic_scl
    values as CONTROL_CORE_PAD0_MCSPI1_SIMO_PAD1_MCSPI1_CS0.MCSPI1_CS0_INPUTENABLE
  [21] I2C1_PMIC_SCL_PWRDOWN rw — Power Down setting for pad i2c1_pmic_scl
    values as CONTROL_CORE_PAD0_MCSPI1_SIMO_PAD1_MCSPI1_CS0.MCSPI1_CS0_PWRDOWN
  [20] I2C1_PMIC_SCL_PULLTYPESELECT rw — Pull-Up/Down selection for pad i2c1_pmic_scl
    0=Pull-Down selected; 1=Pull-Up selected
  [19] I2C1_PMIC_SCL_PULLUDENABLE rw — Pull-Up/Down enable for pad i2c1_pmic_scl
    values as CONTROL_CORE_PAD0_MCSPI1_SIMO_PAD1_MCSPI1_CS0.MCSPI1_CS0_PULLUDENABLE
  [4] USBD0_HS_DM_PULLTYPESELECT rw — Pull-Up/Down selection for pad usbd0_hs_dm
    0=Pull-Down selected; 1=Pull-Up selected
  [3] USBD0_HS_DM_PULLUDENABLE rw — Pull-Up/Down enable for pad usbd0_hs_dm
    values as CONTROL_CORE_PAD0_MCSPI1_SIMO_PAD1_MCSPI1_CS0.MCSPI1_CS0_PULLUDENABLE
  [2:0] USBD0_HS_DM_MUXMODE rw — Functional multiplexing selection for pad usbd0_hs_dm
    0=SEL_USBD0_HS_DM (Select usbd0_hs_dm); 4=SEL_UART3_TX_IRTX (Select uart3_tx_irtx); 7=SEL_SAFE_MODE_CORE196 (Select safe_mode_core196)
0x1F4 CONTROL_CORE_PAD0_I2C1_PMIC_SDA_PAD1_USBD0_SS_RX reset 0x100 — Register control for Pads i2c1_pmic_sda and usbd0_ss_rx Access conditions. Read: unrestricted, Write: unrestricted
  [31] USBD0_SS_RX_WAKEUPEVENT ro — Pad_x wake-up event status latched in the IO
    values as CONTROL_CORE_PAD0_MCSPI1_SIMO_PAD1_MCSPI1_CS0.MCSPI1_CS0_WAKEUPEVENT
  [30] USBD0_SS_RX_WAKEUPENABLE rw — Input pad wake-up enable
    values as CONTROL_CORE_PAD0_MCSPI1_SIMO_PAD1_MCSPI1_CS0.MCSPI1_CS0_WAKEUPENABLE
  [8] I2C1_PMIC_SDA_INPUTENABLE rw — Input enable value for pad i2c1_pmic_sda
    values as CONTROL_CORE_PAD0_MCSPI1_SIMO_PAD1_MCSPI1_CS0.MCSPI1_CS0_INPUTENABLE
  [5] I2C1_PMIC_SDA_PWRDOWN rw — Power Down setting for pad i2c1_pmic_sda
    values as CONTROL_CORE_PAD0_MCSPI1_SIMO_PAD1_MCSPI1_CS0.MCSPI1_CS0_PWRDOWN
  [4] I2C1_PMIC_SDA_PULLTYPESELECT rw — Pull-Up/Down selection for pad i2c1_pmic_sda
    0=Pull-Down selected; 1=Pull-Up selected
  [3] I2C1_PMIC_SDA_PULLUDENABLE rw — Pull-Up/Down enable for pad i2c1_pmic_sda
    values as CONTROL_CORE_PAD0_MCSPI1_SIMO_PAD1_MCSPI1_CS0.MCSPI1_CS0_PULLUDENABLE
0x1FC CONTROL_PADCONF_WAKEUPEVENT_0 ro reset 0x0 — Access conditions. Read: unrestricted, Write: unrestricted
  [all] fields
    1=WakeUp (A wakeup event occurred); 0=No wakeup event occurred
  [31] C2C_DATA9_DUPLICATEWAKEUPEVENT — Wake-up event status latched in the IO for pad c2c_data9
  [30] C2C_DATA8_DUPLICATEWAKEUPEVENT — Wake-up event status latched in the IO for pad c2c_data8
  [n+22] C2C_DATAOUT{n}_DUPLICATEWAKEUPEVENT (n=0..7) — Wake-up event status latched in the IO for pad c2c_dataout{n}
  [n+14] C2C_DATAIN{n}_DUPLICATEWAKEUPEVENT (n=0..7) — Wake-up event status latched in the IO for pad c2c_datain{n}
  [13] C2C_CLKIN1_DUPLICATEWAKEUPEVENT — Wake-up event status latched in the IO for pad c2c_clkin1
  [12] C2C_CLKIN0_DUPLICATEWAKEUPEVENT — Wake-up event status latched in the IO for pad c2c_clkin0
  [11] C2C_CLKOUT1_DUPLICATEWAKEUPEVENT — Wake-up event status latched in the IO for pad c2c_clkout1
  [10] C2C_CLKOUT0_DUPLICATEWAKEUPEVENT — Wake-up event status latched in the IO for pad c2c_clkout0
  [n+2] EMMC_DATA{n}_DUPLICATEWAKEUPEVENT (n=0..7) — Wake-up event status latched in the IO for pad emmc_data{n}
  [1] EMMC_CMD_DUPLICATEWAKEUPEVENT — Wake-up event status latched in the IO for pad emmc_cmd
  [0] EMMC_CLK_DUPLICATEWAKEUPEVENT — Wake-up event status latched in the IO for pad emmc_clk
0x200 CONTROL_PADCONF_WAKEUPEVENT_1 ro reset 0x0 — Access conditions. Read: unrestricted, Write: unrestricted
  [all] fields
    values as the fields of CONTROL_PADCONF_WAKEUPEVENT_0
  [31] UART2_TX_DUPLICATEWAKEUPEVENT — Wake-up event status latched in the IO for pad uart2_tx
  [30] UART2_RX_DUPLICATEWAKEUPEVENT — Wake-up event status latched in the IO for pad uart2_rx
  [29] UART2_CTS_DUPLICATEWAKEUPEVENT — Wake-up event status latched in the IO for pad uart2_cts
  [28] UART2_RTS_DUPLICATEWAKEUPEVENT — Wake-up event status latched in the IO for pad uart2_rts
  [27] HSI2_ACDATA_DUPLICATEWAKEUPEVENT — Wake-up event status latched in the IO for pad hsi2_acdata
  [26] HSI2_ACFLAG_DUPLICATEWAKEUPEVENT — Wake-up event status latched in the IO for pad hsi2_acflag
  [25] HSI2_CADATA_DUPLICATEWAKEUPEVENT — Wake-up event status latched in the IO for pad hsi2_cadata
  [24] HSI2_CAFLAG_DUPLICATEWAKEUPEVENT — Wake-up event status latched in the IO for pad hsi2_caflag
  [23] HSI2_ACWAKE_DUPLICATEWAKEUPEVENT — Wake-up event status latched in the IO for pad hsi2_acwake
  [22] HSI2_CAWAKE_DUPLICATEWAKEUPEVENT — Wake-up event status latched in the IO for pad hsi2_cawake
  [21] HSI2_ACREADY_DUPLICATEWAKEUPEVENT — Wake-up event status latched in the IO for pad hsi2_acready
  [20] HSI2_CAREADY_DUPLICATEWAKEUPEVENT — Wake-up event status latched in the IO for pad hsi2_caready
  [19] UART1_RTS_DUPLICATEWAKEUPEVENT — Wake-up event status latched in the IO for pad uart1_rts
  [18] UART1_RX_DUPLICATEWAKEUPEVENT — Wake-up event status latched in the IO for pad uart1_rx
  [17] UART1_CTS_DUPLICATEWAKEUPEVENT — Wake-up event status latched in the IO for pad uart1_cts
  [16] UART1_TX_DUPLICATEWAKEUPEVENT — Wake-up event status latched in the IO for pad uart1_tx
  [15] HSI1_CADATA_DUPLICATEWAKEUPEVENT — Wake-up event status latched in the IO for pad hsi1_cadata
  [14] HSI1_CAFLAG_DUPLICATEWAKEUPEVENT — Wake-up event status latched in the IO for pad hsi1_caflag
  [13] HSI1_ACDATA_DUPLICATEWAKEUPEVENT — Wake-up event status latched in the IO for pad hsi1_acdata
  [12] HSI1_ACFLAG_DUPLICATEWAKEUPEVENT — Wake-up event status latched in the IO for pad hsi1_acflag
  [11] HSI1_CAWAKE_DUPLICATEWAKEUPEVENT — Wake-up event status latched in the IO for pad hsi1_cawake
  [10] HSI1_ACWAKE_DUPLICATEWAKEUPEVENT — Wake-up event status latched in the IO for pad hsi1_acwake
  [9] HSI1_CAREADY_DUPLICATEWAKEUPEVENT — Wake-up event status latched in the IO for pad hsi1_caready
  [8] HSI1_ACREADY_DUPLICATEWAKEUPEVENT — Wake-up event status latched in the IO for pad hsi1_acready
  [7] LLIB_WAKEREQOUT_DUPLICATEWAKEUPEVENT — Wake-up event status latched in the IO for pad llib_wakereqout
  [6] LLIA_WAKEREQOUT_DUPLICATEWAKEUPEVENT — Wake-up event status latched in the IO for pad llia_wakereqout
  [n-10] C2C_DATA{n}_DUPLICATEWAKEUPEVENT (n=10..15) — Wake-up event status latched in the IO for pad c2c_data{n}
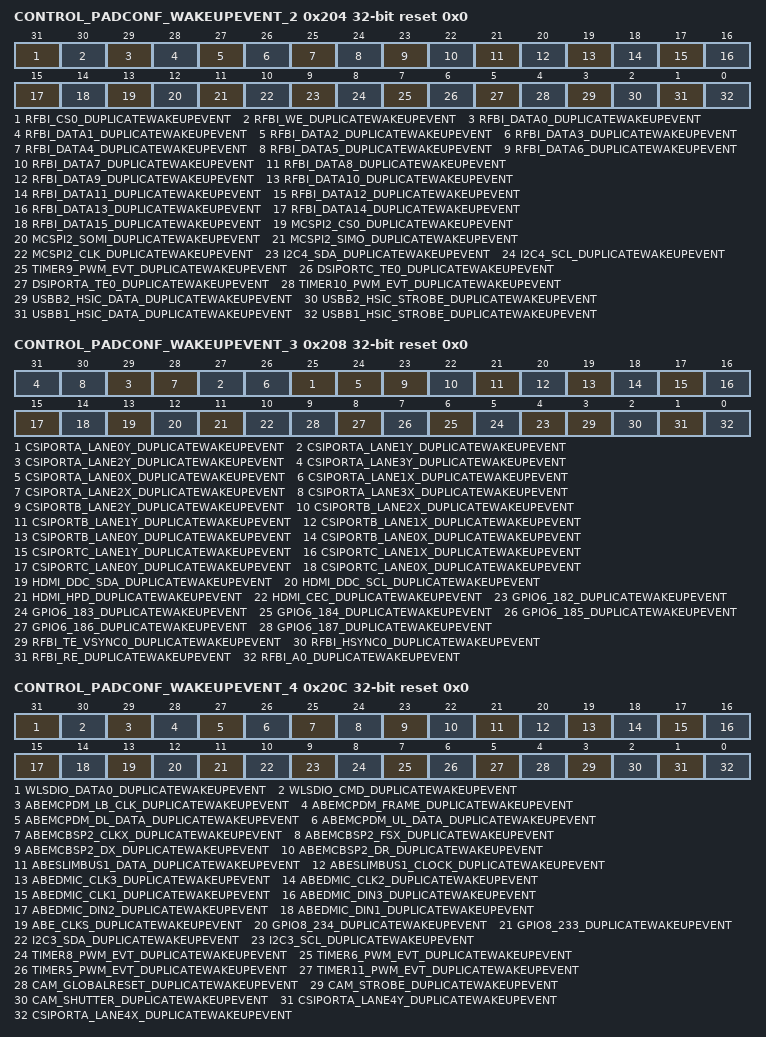
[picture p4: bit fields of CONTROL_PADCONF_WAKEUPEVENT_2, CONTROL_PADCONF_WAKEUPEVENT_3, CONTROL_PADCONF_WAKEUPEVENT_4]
0x204 CONTROL_PADCONF_WAKEUPEVENT_2 ro reset 0x0 — Access conditions. Read: unrestricted, Write: unrestricted
  [all] fields
    values as the fields of CONTROL_PADCONF_WAKEUPEVENT_0
  [31] RFBI_CS0_DUPLICATEWAKEUPEVENT — Wake-up event status latched in the IO for pad rfbi_cs0
  [30] RFBI_WE_DUPLICATEWAKEUPEVENT — Wake-up event status latched in the IO for pad rfbi_we
  [29-n] RFBI_DATA{n}_DUPLICATEWAKEUPEVENT (n=0..15) — Wake-up event status latched in the IO for pad rfbi_data{n}
  [13] MCSPI2_CS0_DUPLICATEWAKEUPEVENT — Wake-up event status latched in the IO for pad mcspi2_cs0
  [12] MCSPI2_SOMI_DUPLICATEWAKEUPEVENT — Wake-up event status latched in the IO for pad mcspi2_somi
  [11] MCSPI2_SIMO_DUPLICATEWAKEUPEVENT — Wake-up event status latched in the IO for pad mcspi2_simo
  [10] MCSPI2_CLK_DUPLICATEWAKEUPEVENT — Wake-up event status latched in the IO for pad mcspi2_clk
  [9] I2C4_SDA_DUPLICATEWAKEUPEVENT — Wake-up event status latched in the IO for pad i2c4_sda
  [8] I2C4_SCL_DUPLICATEWAKEUPEVENT — Wake-up event status latched in the IO for pad i2c4_scl
  [7] TIMER9_PWM_EVT_DUPLICATEWAKEUPEVENT — Wake-up event status latched in the IO for pad timer9_pwm_evt
  [6] DSIPORTC_TE0_DUPLICATEWAKEUPEVENT — Wake-up event status latched in the IO for pad dsiportc_te0
  [5] DSIPORTA_TE0_DUPLICATEWAKEUPEVENT — Wake-up event status latched in the IO for pad dsiporta_te0
  [4] TIMER10_PWM_EVT_DUPLICATEWAKEUPEVENT — Wake-up event status latched in the IO for pad timer10_pwm_evt
  [3] USBB2_HSIC_DATA_DUPLICATEWAKEUPEVENT — Wake-up event status latched in the IO for pad usbb2_hsic_data
  [2] USBB2_HSIC_STROBE_DUPLICATEWAKEUPEVENT — Wake-up event status latched in the IO for pad usbb2_hsic_strobe
  [1] USBB1_HSIC_DATA_DUPLICATEWAKEUPEVENT — Wake-up event status latched in the IO for pad usbb1_hsic_data
  [0] USBB1_HSIC_STROBE_DUPLICATEWAKEUPEVENT — Wake-up event status latched in the IO for pad usbb1_hsic_strobe
0x208 CONTROL_PADCONF_WAKEUPEVENT_3 ro reset 0x0 — Access conditions. Read: unrestricted, Write: unrestricted
  [all] fields
    values as the fields of CONTROL_PADCONF_WAKEUPEVENT_0
  [2n+25] CSIPORTA_LANE{n}Y_DUPLICATEWAKEUPEVENT (n=0..3) — Wake-up event status latched in the IO for pad csiporta_lane{n}y
  [2n+24] CSIPORTA_LANE{n}X_DUPLICATEWAKEUPEVENT (n=0..3) — Wake-up event status latched in the IO for pad csiporta_lane{n}x
  [23] CSIPORTB_LANE2Y_DUPLICATEWAKEUPEVENT — Wake-up event status latched in the IO for pad csiportb_lane2y
  [22] CSIPORTB_LANE2X_DUPLICATEWAKEUPEVENT — Wake-up event status latched in the IO for pad csiportb_lane2x
  [21] CSIPORTB_LANE1Y_DUPLICATEWAKEUPEVENT — Wake-up event status latched in the IO for pad csiportb_lane1y
  [20] CSIPORTB_LANE1X_DUPLICATEWAKEUPEVENT — Wake-up event status latched in the IO for pad csiportb_lane1x
  [19] CSIPORTB_LANE0Y_DUPLICATEWAKEUPEVENT — Wake-up event status latched in the IO for pad csiportb_lane0y
  [18] CSIPORTB_LANE0X_DUPLICATEWAKEUPEVENT — Wake-up event status latched in the IO for pad csiportb_lane0x
  [17] CSIPORTC_LANE1Y_DUPLICATEWAKEUPEVENT — Wake-up event status latched in the IO for pad csiportc_lane1y
  [16] CSIPORTC_LANE1X_DUPLICATEWAKEUPEVENT — Wake-up event status latched in the IO for pad csiportc_lane1x
  [15] CSIPORTC_LANE0Y_DUPLICATEWAKEUPEVENT — Wake-up event status latched in the IO for pad csiportc_lane0y
  [14] CSIPORTC_LANE0X_DUPLICATEWAKEUPEVENT — Wake-up event status latched in the IO for pad csiportc_lane0x
  [13] HDMI_DDC_SDA_DUPLICATEWAKEUPEVENT — Wake-up event status latched in the IO for pad hdmi_ddc_sda
  [12] HDMI_DDC_SCL_DUPLICATEWAKEUPEVENT — Wake-up event status latched in the IO for pad hdmi_ddc_scl
  [11] HDMI_HPD_DUPLICATEWAKEUPEVENT — Wake-up event status latched in the IO for pad hdmi_hpd
  [10] HDMI_CEC_DUPLICATEWAKEUPEVENT — Wake-up event status latched in the IO for pad hdmi_cec
  [n-178] GPIO6_{n}_DUPLICATEWAKEUPEVENT (n=182..187) — Wake-up event status latched in the IO for pad gpio6_{n}
  [3] RFBI_TE_VSYNC0_DUPLICATEWAKEUPEVENT — Wake-up event status latched in the IO for pad rfbi_te_vsync0
  [2] RFBI_HSYNC0_DUPLICATEWAKEUPEVENT — Wake-up event status latched in the IO for pad rfbi_hsync0
  [1] RFBI_RE_DUPLICATEWAKEUPEVENT — Wake-up event status latched in the IO for pad rfbi_re
  [0] RFBI_A0_DUPLICATEWAKEUPEVENT — Wake-up event status latched in the IO for pad rfbi_a0
0x20C CONTROL_PADCONF_WAKEUPEVENT_4 ro reset 0x0 — Access conditions. Read: unrestricted, Write: unrestricted
  [all] fields
    values as the fields of CONTROL_PADCONF_WAKEUPEVENT_0
  [31] WLSDIO_DATA0_DUPLICATEWAKEUPEVENT — Wake-up event status latched in the IO for pad wlsdio_data0
  [30] WLSDIO_CMD_DUPLICATEWAKEUPEVENT — Wake-up event status latched in the IO for pad wlsdio_cmd
  [29] ABEMCPDM_LB_CLK_DUPLICATEWAKEUPEVENT — Wake-up event status latched in the IO for pad abemcpdm_lb_clk
  [28] ABEMCPDM_FRAME_DUPLICATEWAKEUPEVENT — Wake-up event status latched in the IO for pad abemcpdm_frame
  [27] ABEMCPDM_DL_DATA_DUPLICATEWAKEUPEVENT — Wake-up event status latched in the IO for pad abemcpdm_dl_data
  [26] ABEMCPDM_UL_DATA_DUPLICATEWAKEUPEVENT — Wake-up event status latched in the IO for pad abemcpdm_ul_data
  [25] ABEMCBSP2_CLKX_DUPLICATEWAKEUPEVENT — Wake-up event status latched in the IO for pad abemcbsp2_clkx
  [24] ABEMCBSP2_FSX_DUPLICATEWAKEUPEVENT — Wake-up event status latched in the IO for pad abemcbsp2_fsx
  [23] ABEMCBSP2_DX_DUPLICATEWAKEUPEVENT — Wake-up event status latched in the IO for pad abemcbsp2_dx
  [22] ABEMCBSP2_DR_DUPLICATEWAKEUPEVENT — Wake-up event status latched in the IO for pad abemcbsp2_dr
  [21] ABESLIMBUS1_DATA_DUPLICATEWAKEUPEVENT — Wake-up event status latched in the IO for pad abeslimbus1_data
  [20] ABESLIMBUS1_CLOCK_DUPLICATEWAKEUPEVENT — Wake-up event status latched in the IO for pad abeslimbus1_clock
  [19] ABEDMIC_CLK3_DUPLICATEWAKEUPEVENT — Wake-up event status latched in the IO for pad abedmic_clk3
  [18] ABEDMIC_CLK2_DUPLICATEWAKEUPEVENT — Wake-up event status latched in the IO for pad abedmic_clk2
  [17] ABEDMIC_CLK1_DUPLICATEWAKEUPEVENT — Wake-up event status latched in the IO for pad abedmic_clk1
  [16] ABEDMIC_DIN3_DUPLICATEWAKEUPEVENT — Wake-up event status latched in the IO for pad abedmic_din3
  [15] ABEDMIC_DIN2_DUPLICATEWAKEUPEVENT — Wake-up event status latched in the IO for pad abedmic_din2
  [14] ABEDMIC_DIN1_DUPLICATEWAKEUPEVENT — Wake-up event status latched in the IO for pad abedmic_din1
  [13] ABE_CLKS_DUPLICATEWAKEUPEVENT — Wake-up event status latched in the IO for pad abe_clks
  [12] GPIO8_234_DUPLICATEWAKEUPEVENT — Wake-up event status latched in the IO for pad gpio8_234
  [11] GPIO8_233_DUPLICATEWAKEUPEVENT — Wake-up event status latched in the IO for pad gpio8_233
  [10] I2C3_SDA_DUPLICATEWAKEUPEVENT — Wake-up event status latched in the IO for pad i2c3_sda
  [9] I2C3_SCL_DUPLICATEWAKEUPEVENT — Wake-up event status latched in the IO for pad i2c3_scl
  [8] TIMER8_PWM_EVT_DUPLICATEWAKEUPEVENT — Wake-up event status latched in the IO for pad timer8_pwm_evt
  [7] TIMER6_PWM_EVT_DUPLICATEWAKEUPEVENT — Wake-up event status latched in the IO for pad timer6_pwm_evt
  [6] TIMER5_PWM_EVT_DUPLICATEWAKEUPEVENT — Wake-up event status latched in the IO for pad timer5_pwm_evt
  [5] TIMER11_PWM_EVT_DUPLICATEWAKEUPEVENT — Wake-up event status latched in the IO for pad timer11_pwm_evt
  [4] CAM_GLOBALRESET_DUPLICATEWAKEUPEVENT — Wake-up event status latched in the IO for pad cam_globalreset
  [3] CAM_STROBE_DUPLICATEWAKEUPEVENT — Wake-up event status latched in the IO for pad cam_strobe
  [2] CAM_SHUTTER_DUPLICATEWAKEUPEVENT — Wake-up event status latched in the IO for pad cam_shutter
  [1] CSIPORTA_LANE4Y_DUPLICATEWAKEUPEVENT — Wake-up event status latched in the IO for pad csiporta_lane4y
  [0] CSIPORTA_LANE4X_DUPLICATEWAKEUPEVENT — Wake-up event status latched in the IO for pad csiporta_lane4x
